# R7KA8D2AD register map
Vendor: Renesas Electronics Corporation; Series: RA8; File version: 1.10.02
CPU: CM85 r0p2, little endian, MPU, FPU, VTOR, 4 interrupt priority bits, 96 interrupts
Registers are 32-bit, read-write, reset 0x0 unless marked. A register's access mark holds for its fields unless they carry their own. Offsets are from the block's base; [hi:lo] are bit positions; {n}, {i} and the like mark numbered series; 'fields as' and 'values as' point back to an identical list.

## OSPI0_B — Octa Serial Peripheral Interface
Base 0x40268000
Same registers: OSPI1_B 0x40268400, OSPI0_B_NS 0x50268000, OSPI1_B_NS 0x50268400
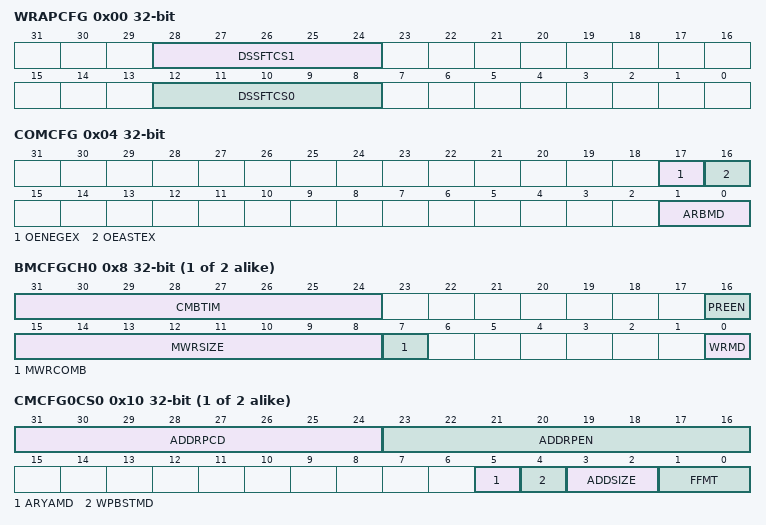
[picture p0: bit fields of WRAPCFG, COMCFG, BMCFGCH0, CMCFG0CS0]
0x00 WRAPCFG — OSPI Wrapper Configuration Register
  [28:24] DSSFTCS1 — DS Shift for Slave 1
  [12:8] DSSFTCS0 — DS Shift for Slave 0
0x04 COMCFG — OSPI Common Configuration Register
  [17] OENEGEX — Output Enable Negating Extension
    0=Do not extend one cycle output enable; 1=Extend one cycle output enable
  [16] OEASTEX — Output Enable Asserting Extension
    values as OENEGEX
  [1:0] ARBMD — Channel Arbitration Mode
    0=Round-robin (ch0-ch1-ch0-ch1…); 1=Always ch0 win; 2=Always ch1 win
{0x8+4i} BMCFGCH{i} (i=0..1) — OSPI Bridge Map Configuration Register Chn (n = 0, 1)
  [31:24] CMBTIM — Combination Timer
  [16] PREEN — Prefetch Enable
    0=Disable prefetch function; 1=Enable prefetch function
  [15:8] MWRSIZE — Memory Write Size
  [7] MWRCOMB — Memory Write Combination Mode
    0=Disable combination mode; 1=Enable combination mode
  [0] WRMD — System Bus Write Response Mode
    0=Return response after storing to the internal write buffer; 1=Return response after issuing a write transaction to the xSPI bus
{0x10+0x10*i} CMCFG0CS{i} (i=0..1) — OSPI Command Map Configuration Register 0 CSn
  [31:24] ADDRPCD — Address Replace Code
  [23:16] ADDRPEN — Address Replace Enable
    0=No replacement (xSPI frame address field is the same as system bus address); 1=Replacement
  [5] ARYAMD — Array Address Mode
    0=Normal address mode; 1=Array address mode
  [4] WPBSTMD — Wrapping Burst Mode
    0=Separate xSPI transfer at the wrapping address boundary; 1=Do not separate xSPI transfer at the wrapping address boundary
  [3:2] ADDSIZE — Address Size
    0=1 byte (256-byte address space); 1=2 bytes (64-KB address space); 2=3 bytes (16-MB address space); 3=4 bytes (4-GB address space)
  [1:0] FFMT — Frame Format
    0=Normal format: Command 1 byte, address ADDSIZE, data up to system bus transaction; 1=8D-8D-8D profile 1.0 format: Command 2 bytes, address ADDSIZE, data up to system bus transaction; 2=8D-8D-8D profile 2.0 Command Modifier format: Command & Modifier 6 bytes, data up to system bus transaction; 3=8D-8D-8D profile 2.0 Commands with Extended Command Modifier format: Command & Modifier 6 bytes, data up to system bus transaction
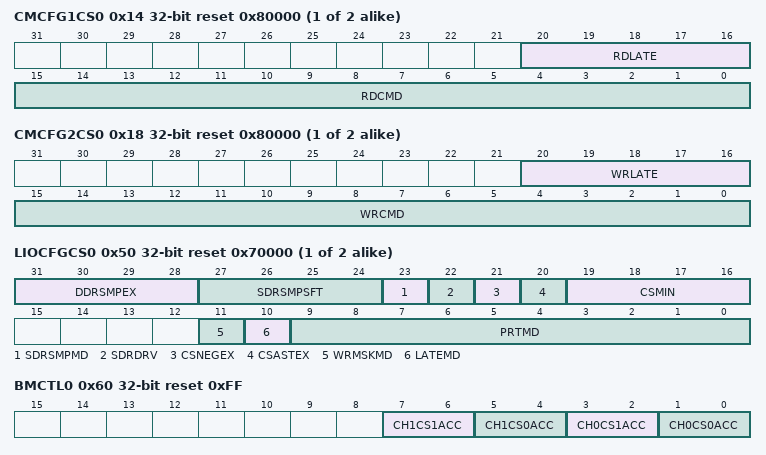
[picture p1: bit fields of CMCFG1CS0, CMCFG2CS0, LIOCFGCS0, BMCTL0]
{0x14+0x10*i} CMCFG1CS{i} (i=0..1) reset 0x80000 — OSPI Command Map Configuration Register 1 CSn
  [20:16] RDLATE — Read Latency Cycle
  [15:0] RDCMD — Read Command
{0x18+0x10*i} CMCFG2CS{i} (i=0..1) reset 0x80000 — OSPI Command Map Configuration Register 2 CSn
  [20:16] WRLATE — Write Latency Cycle
  [15:0] WRCMD — Write Command
{0x50+4i} LIOCFGCS{i} (i=0..1) reset 0x70000 — OSPI Link I/O Configuration Register CSn
  [31:28] DDRSMPEX — DDR Sampling Window Extend
  [27:24] SDRSMPSFT — SDR Sampling window shift
  [23] SDRSMPMD — SDR Sampling Mode
    0=Samples data input at falling edge; 1=Samples data input at rising edge
  [22] SDRDRV — SDR Driving Timing
    0=Drive at 1/2 cycle before CK rising edge; 1=Drive at CK rising-edge
  [21] CSNEGEX — CS Negating Extension
    0=No extension; 1=Extend 1 cycle
  [20] CSASTEX — CS Asserting Extension
    0=No extension; 1=Extend 1 cycle
  [19:16] CSMIN — CS Minimum Idle Term
  [11] WRMSKMD — Write Mask Mode
    0=Write mask disable; 1=Write mask enable
  [10] LATEMD — Latency Mode
  [9:0] PRTMD — Protocol Mode
    0=1S-1S-1S; 0x3B2=4S-4D-4D; 0x3FF=8D-8D-8D; 72=1S-2S-2S; 73=2S-2S-2S; 144=1S-4S-4S; 146=4S-4S-4S; other=Others (Setting prohibited)
0x60 BMCTL0 reset 0xFF — OSPI Bridge Map Control Register 0
  [all] fields
    0=Read/write disable; 1=Read enable, write disable; 2=Read disable, write enable; 3=Read/write enable
  [7:6] CH1CS1ACC — System bus ch1 to slave 1 memory area access enable
  [5:4] CH1CS0ACC — System bus ch1 to slave 0 memory area access enable
  [3:2] CH0CS1ACC — System bus ch0 to slave 1 memory area access enable
  [1:0] CH0CS0ACC — System bus ch0 to slave 0 memory area access enable
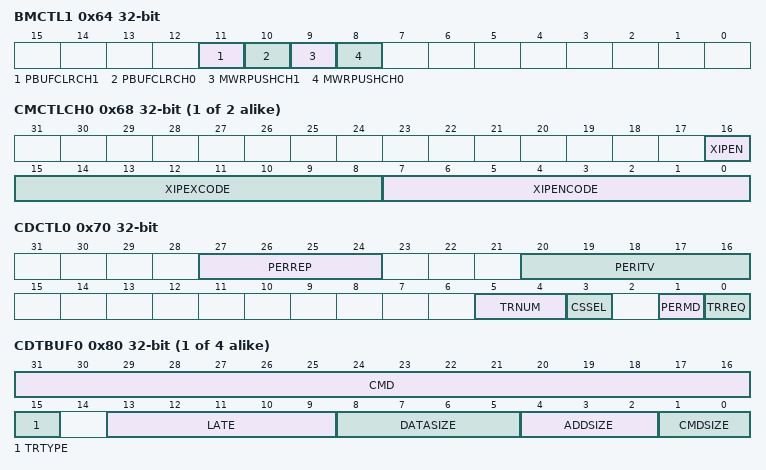
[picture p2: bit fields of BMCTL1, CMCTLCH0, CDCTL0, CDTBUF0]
0x64 BMCTL1 wo — OSPI Bridge Map Control Register 1
  [11] PBUFCLRCH1 — Prefetch Buffer Clear for ch1
  [10] PBUFCLRCH0 — Prefetch Buffer Clear for ch0
    0=No command; 1=Clear request
  [9] MWRPUSHCH1 — Memory Write Data Push for ch1
  [8] MWRPUSHCH0 — Memory Write Data Push for ch0
    0=No command; 1=Push request
{0x68+4i} CMCTLCH{i} (i=0..1) — OSPI Command Map Control Register CHn (n = 0, 1)
  [16] XIPEN — XiP Mode Enable
    0=Disable XiP mode; 1=Enable XiP mode
  [15:8] XIPEXCODE — XiP Mode Exit Code
  [7:0] XIPENCODE — XiP Mode Enter Code
0x70 CDCTL0 — OSPI Command Manual Control Register 0
  [27:24] PERREP — Periodic Transaction Repeat
  [20:16] PERITV — Periodic Transaction Interval
  [5:4] TRNUM — Transaction Number
    0=Issue 1 command (using command buffer 0); 1=Issue 2 commands (using command buffer 0-1); 2=Issue 3 commands (using command buffer 0-2); 3=Issue 4 commands (using command buffer 0-3)
  [3] CSSEL — Chip Select
    0=CS0; 1=CS1
  [1] PERMD — Periodic Mode
    0=Direct manual-command mode; 1=Periodic manual-command mode
  [0] TRREQ — Transaction Request
    0=No transaction; 1=Request transaction
0x74 CDCTL1 — OSPI Command Manual Control Register 1
  [31:0] PEREXP — Periodic Transaction Expected Value
0x78 CDCTL2 — OSPI Command Manual Control Register 2
  [31:0] PERMSK — Periodic Transaction Masked Value
{0x80+0x10*i} CDTBUF{i} (i=0..3) — OSPI Command Manual Type Buf {i}
  [31:16] CMD — Command (1-2 bytes)
  [15] TRTYPE — Transaction Type
    0=Read transaction (readout data from slave device); 1=Not read transaction
  [13:9] LATE — Latency Cycle
  [8:5] DATASIZE — Write/Read Data Size
  [4:2] ADDSIZE — Address Size
    0=0 bytes (no address phase); 1=1 byte; 2=2 bytes; 3=3 bytes; 4=4 bytes; other=Others (Setting prohibited)
  [1:0] CMDSIZE — Command Size
    0=0 bytes (no command phase); 1=1 byte; 2=2 bytes; other=Others (Setting prohibited)
{0x84+0x10*i} CDABUF{i} (i=0..3) — OSPI Command Manual Address Buf {i}
  [31:0] ADD — Address
{0x88+0x10*i} CDD0BUF{i} (i=0..3) — OSPI Command Manual Data 0 Buf {i}
  [31:0] DATA — Write/Read Data
{0x8C+0x10*i} CDD1BUF{i} (i=0..3) — OSPI Command Manual Data 1 Buf {i}
  [31:0] DATA — Write/Read Data
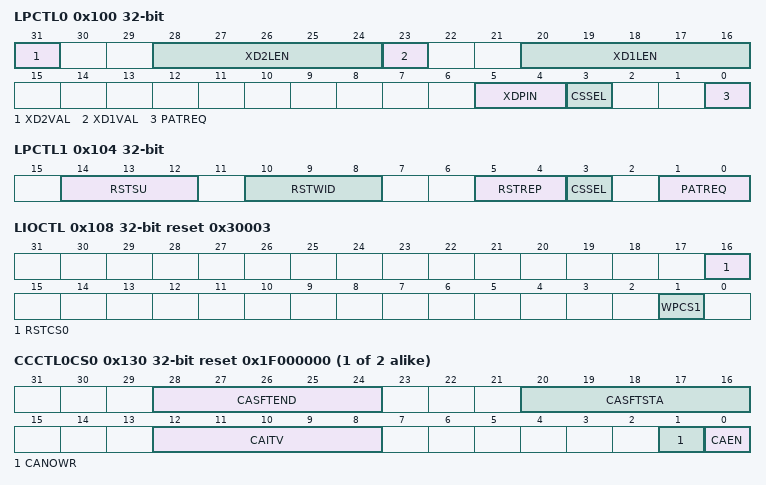
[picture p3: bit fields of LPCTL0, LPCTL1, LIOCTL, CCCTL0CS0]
0x100 LPCTL0 — OSPI Link Pattern Control Register 0
  [31] XD2VAL — XiP Disable Pattern 2nd Phase Value
    0=Low drive; 1=High drive
  [28:24] XD2LEN — XiP Disable Pattern 2nd Phase Length
  [23] XD1VAL — XiP Disable Pattern 1st Phase Value
    0=Low drive; 1=High drive
  [20:16] XD1LEN — XiP Disable Pattern 1st Phase Length
  [5:4] XDPIN — XiP Disable Pattern Pin
    0=1 pin; 1=2 pins; 2=4 pins; 3=8 pins
  [3] CSSEL — Chip Select
    0=Slave 0 (CS0); 1=Slave 1 (CS1)
  [0] PATREQ — Pattern Request
    0=No request XiP disable pattern; 1=Request XiP disable pattern
0x104 LPCTL1 — OSPI Link Pattern Control Register 1
  [14:12] RSTSU — Reset Pattern Data Output Setup Time
  [10:8] RSTWID — Reset Pattern Width
  [5:4] RSTREP — Reset Pattern Repeat
    0=4 times (specified on Reset Signaling Protocol); 1=5 times; 2=6 times; 3=7 times
  [3] CSSEL — Chip select
    0=Slave 0 (CS0); 1=Slave 1 (CS1)
  [1:0] PATREQ — Pattern Request
    0=No request; 1=Request Reset pattern; 2=Request CS-only pattern; 3=Setting prohibited
0x108 LIOCTL reset 0x30003 — OSPI Link I/O Control Register
  [16] RSTCS0 — Reset Drive
    0=Drive low level; 1=Drive high level
  [1] WPCS1 — WP Drive for Slave 1
    0=Drive low level; 1=Drive high level
{0x130+0x20*i} CCCTL0CS{i} (i=0..1) reset 0x1F000000 — OSPI Command Calibration Control Register 0 CSn
  [28:24] CASFTEND — Calibration DS Shift End Value
  [20:16] CASFTSTA — Calibration DS Shift Start Value
  [12:8] CAITV — Calibration Interval
  [1] CANOWR — Calibration No Write Mode
    0=Calibration sequence with write command; 1=Calibration sequence without write command
  [0] CAEN — Automatic Calibration Enable
    0=Disable automatic calibration; 1=Enable automatic calibration
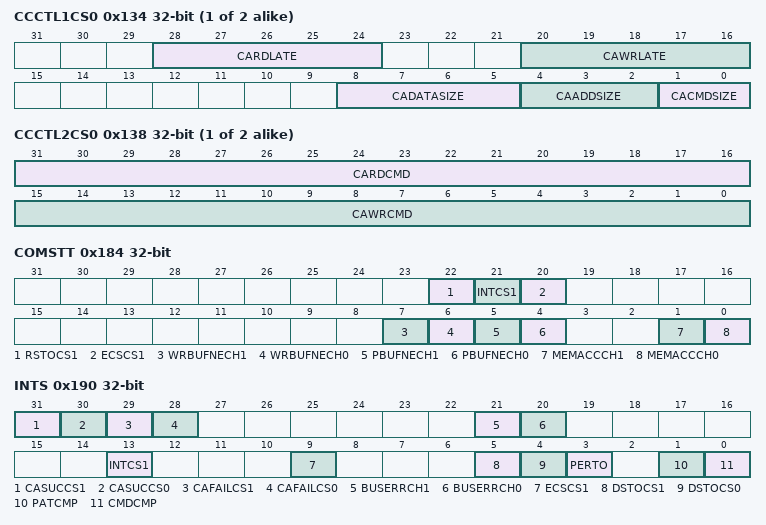
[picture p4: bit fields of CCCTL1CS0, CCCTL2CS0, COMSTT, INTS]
{0x134+0x20*i} CCCTL1CS{i} (i=0..1) — OSPI Command Calibration Control Register 1 CSn
  [28:24] CARDLATE — Read Latency Cycle
  [20:16] CAWRLATE — Write Latency Cycle
  [8:5] CADATASIZE — Write/Read Data Size
  [4:2] CAADDSIZE — Address Size
    values as CDTBUF0.ADDSIZE
  [1:0] CACMDSIZE — Command Size
    0=0 bytes (no command phase); 1=1 byte; 2=2 bytes; 3=Setting prohibited
{0x138+0x20*i} CCCTL2CS{i} (i=0..1) — OSPI Command Calibration Control Register 2 CSn
  [31:16] CARDCMD — Calibration Pattern Read Command
  [15:0] CAWRCMD — Calibration Pattern Write Command
{0x13C+0x20*i} CCCTL3CS{i} (i=0..1) — OSPI Command Calibration Control Register 3 CSn
  [31:0] CAADD — Calibration Pattern Address
{0x140+0x20*i} CCCTL4CS{i} (i=0..1) — OSPI Command Calibration Control Register 4 CSn
  [31:0] CADATA — Calibration Pattern Data
{0x144+0x20*i} CCCTL5CS{i} (i=0..1) — OSPI Command Calibration Control Register 5 CSn
  [31:0] CADATA — Calibration Pattern Data
{0x148+0x20*i} CCCTL6CS{i} (i=0..1) — OSPI Command Calibration Control Register 6 CSn
  [31:0] CADATA — Calibration Pattern Data
{0x14C+0x20*i} CCCTL7CS{i} (i=0..1) — OSPI Command Calibration Control Register 7 CSn
  [31:0] CADATA — Calibration Pattern Data
0x184 COMSTT ro — OSPI Common Status Register
  [22] RSTOCS1 — RSTO Monitor for Slave 1
    0=Low level; 1=High level
  [21] INTCS1 — INT Monitor for Slave 1
    0=Low level; 1=High level
  [20] ECSCS1 — ECS Monitor for Slave 1
    0=Low level; 1=High level
  [7] WRBUFNECH1 — Write Buffer Not Empty for Channel 1
  [6] WRBUFNECH0 — Write Buffer Not Empty for Channel 0
    0=Empty; 1=Not empty
  [5] PBUFNECH1 — Prefetch Buffer Not Empty for Channel 1
  [4] PBUFNECH0 — Prefetch Buffer Not Empty for Channel 0
    0=Empty; 1=Not empty
  [1] MEMACCCH1 — Memory Access Ongoing from Channel 1
  [0] MEMACCCH0 — Memory Access Ongoing from Channel 0
    0=System bus bridge CH0 is not accessing to memory; 1=System bus bridge CH0 is accessing to memory
{0x188+4i} CASTTCS{i} (i=0..1) ro — OSPI Calibration Status Register CSn
  [31:0] CASUC — Calibration Success
0x190 INTS ro — OSPI Interrupt Status Register
  [31] CASUCCS1 — Calibration Success for Slave 1
    0=No detection; 1=Detection
  [30] CASUCCS0 — Calibration Success for Slave 0
    0=No detection; 1=Detection
  [29] CAFAILCS1 — Calibration Failed for Slave 1
    0=No detection; 1=Detection
  [28] CAFAILCS0 — Calibration Failed for Slave 0
    0=No detection; 1=Detection
  [21] BUSERRCH1 — System Bus Error for Channel 1
  [20] BUSERRCH0 — System Bus Error for Channel 0
  [13] INTCS1 — Interrupt Detection for Slave 1
    0=No detection; 1=Detection
  [9] ECSCS1 — ECC Error Detection for Slave 1
    0=No detection; 1=Detection
  [5] DSTOCS1 — DS Timeout for Slave 1
    0=No detection; 1=Detection
  [4] DSTOCS0 — DS Timeout for Slave 0
    0=No detection; 1=Detection
  [3] PERTO — Periodic Transaction Timeout
    0=No detection; 1=Detection
  [1] PATCMP — Pattern Completed
    0=No detection; 1=Detection
  [0] CMDCMP — Command Completed
    0=No detection; 1=Detection
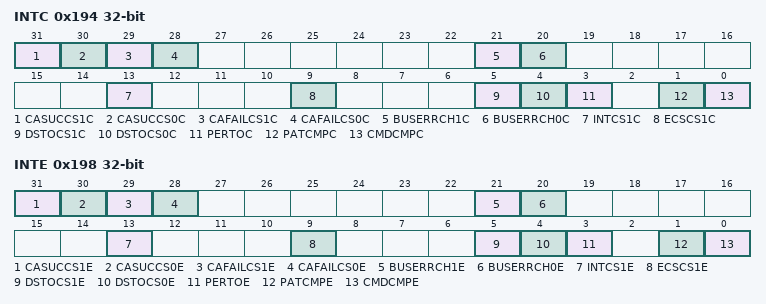
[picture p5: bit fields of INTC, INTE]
0x194 INTC wo — OSPI Interrupt Clear Register
  [all] fields
    0=No change interrupt status; 1=Clear interrupt status
  [31] CASUCCS1C — Calibration Success for Slave 1 Interrupt Clear
  [30] CASUCCS0C — Calibration Success for Slave 0 Interrupt Clear
  [29] CAFAILCS1C — Calibration Failed for Slave 1 Interrupt Clear
  [28] CAFAILCS0C — Calibration Failed for Slave 0 Interrupt Clear
  [21] BUSERRCH1C — System Bus Error for ch1 Interrupt Clear
  [20] BUSERRCH0C — System Bus Error for ch0 Interrupt Clear
  [13] INTCS1C — Interrupt Detection for Slave 1 Interrupt Clear
  [9] ECSCS1C — ECC Error Detection for Slave 1 Interrupt Clear
  [5] DSTOCS1C — DS Timeout for Slave 1 Interrupt Clear
  [4] DSTOCS0C — DS Timeout for Slave 0 Interrupt Clear
  [3] PERTOC — Periodic Transaction Timeout Interrupt Clear
  [1] PATCMPC — Pattern Completed Interrupt Clear
  [0] CMDCMPC — Command Completed Interrupt Clear
0x198 INTE — OSPI Interrupt Enable Register
  [all] fields
    0=Disabled; 1=Enabled
  [31] CASUCCS1E — Calibration Success for Slave 1 Interrupt Enable
  [30] CASUCCS0E — Calibration Success for Slave 0 Interrupt Enable
  [29] CAFAILCS1E — Calibration Failed for Slave 1 Interrupt Enable
  [28] CAFAILCS0E — Calibration Failed for Slave 0 Interrupt Enable
  [21] BUSERRCH1E — System Bus Error for ch1 Interrupt Enable
  [20] BUSERRCH0E — System Bus Error for ch0 Interrupt Enable
  [13] INTCS1E — Interrupt Detection for Slave 1 Interrupt Enable
  [9] ECSCS1E — ECC Error Detection for Slave 1 Interrupt Enable
  [5] DSTOCS1E — DS Timeout for Slave 1 Interrupt Enable
  [4] DSTOCS0E — DS Timeout for Slave 0 Interrupt Enable
  [3] PERTOE — Periodic Transaction Timeout Interrupt Enable
  [1] PATCMPE — Pattern Completed Interrupt Enable
  [0] CMDCMPE — Command Completed Interrupt Enable
